# CC27x0 register map
File version: 1.0
CPU: CM4 r0p4, little endian, no MPU, no FPU, VTOR, 3 interrupt priority bits
Registers are 32-bit, read-write, reset 0x0 unless marked. A register's access mark holds for its fields unless they carry their own. Offsets are from the block's base; [hi:lo] are bit positions; {n}, {i} and the like mark numbered series; 'fields as' and 'values as' point back to an identical list.

## CLKCTL — This component is the clock controller. Here SW can turn on and off IP clocks and read IP and system clock status.
Base 0x40020000
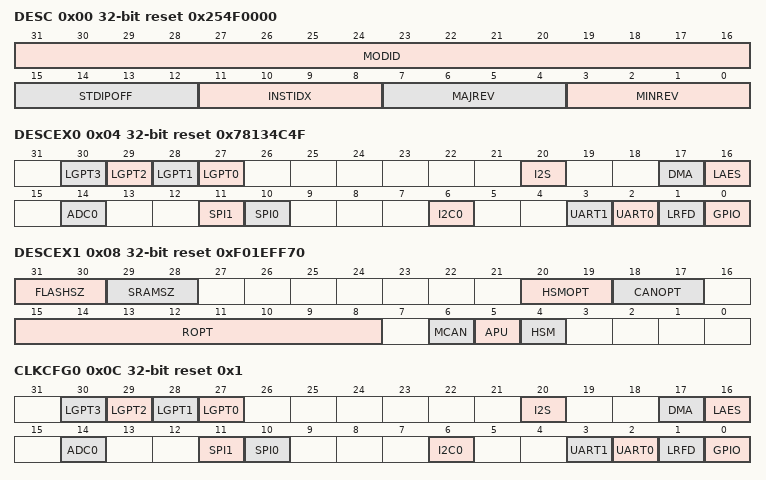
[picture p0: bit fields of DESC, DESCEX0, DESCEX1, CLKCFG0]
0x00 DESC ro reset 0x254F0000 — Description Register. This register provides IP module ID, revision information, instance index and standard MMR registers offset.
  [31:16] MODID — Module identifier used to uniquely identify this IP.
  [15:12] STDIPOFF — Standard IP MMR block offset. Standard IP MMRs are the set of from aggregated IRQ registers till DTB. 0: Standard IP MMRs do not exist 0x1-0xF: Standard IP MMRs begin at offset of (64*STDIPOFF from the base IP address)
  [11:8] INSTIDX — IP Instance ID number. If multiple instances of IP exist in the device, this field can identify the instance number (0-15).
  [7:4] MAJREV — Major revision of IP 0-15
  [3:0] MINREV — Minor revision of IP 0-15.
0x04 DESCEX0 ro reset 0x78134C4F — Extended Description Register 0. This register shows SVT IP availability, HW features and memory size configuration.
  [all] fields
    1=IP_AVAIL (IP is available); 0=IP_UNAVAIL (IP is unavailable)
  [n+27] LGPT{n} (n=0..3) — IP status on device
  [20] I2S — IP status on device
  [17] DMA — IP status on device
  [16] LAES — IP status on device
  [14] ADC0 — IP status on device
  [11] SPI1 — IP status on device
  [10] SPI0 — IP status on device
  [6] I2C0 — IP status on device
  [3] UART1 — IP status on device
  [2] UART0 — IP status on device
  [1] LRFD — IP status on device
  [0] GPIO — IP status on device
0x08 DESCEX1 ro reset 0xF01EFF70 — Extended Description Register 1. This register shows SVT IP availability, HW features and memory size configuration.
  [31:30] FLASHSZ — System flash availability
    3=SZ3 (Flash size set to level 3 (Max size)); 2=SZ2 (Flash size set to level 2); 1=SZ1 (Flash size set to level 1); 0=SZ0 (Flash size set to level 0 (Min size))
  [29:28] SRAMSZ — System SRAM availability
    3=SZ3 (SRAM size set to level 3 (Max size)); 2=SZ2 (SRAM size set to level 2); 1=SZ1 (SRAM size set to level 1); 0=SZ0 (SRAM size set to level 0 (Min size))
  [20:19] HSMOPT — HSM IP feature availability.
    3=MAX (All features available)
  [18:17] CANOPT — CAN IP feature availability
    3=MAX (All features available)
  [15:8] ROPT — System radio feature availability
    255=MAX (All features available)
  [6] MCAN — IP status on device
    values as the fields of DESCEX0
  [5] APU — IP status on device
    values as the fields of DESCEX0
  [4] HSM — IP status on device
    values as the fields of DESCEX0
0x0C CLKCFG0 ro reset 0x1 — Clock Configuration Register 0. This register shows the IP clock configuration for the system. The configuration is updated through CLKENSET0 and CLKENCLR0.
  [all] fields
    1=CLK_EN (Clock is enabled); 0=CLK_DIS (Clock is disabled)
  [n+27] LGPT{n} (n=0..3) — IP clock configuration
  [20] I2S — IP clock configuration
  [17] DMA — IP clock configuration
  [16] LAES — IP clock configuration
  [14] ADC0 — IP clock configuration
  [11] SPI1 — IP clock configuration
  [10] SPI0 — IP clock configuration
  [6] I2C0 — IP clock configuration
  [3] UART1 — IP clock configuration
  [2] UART0 — IP clock configuration
  [1] LRFD — IP clock configuration
  [0] GPIO — IP clock configuration
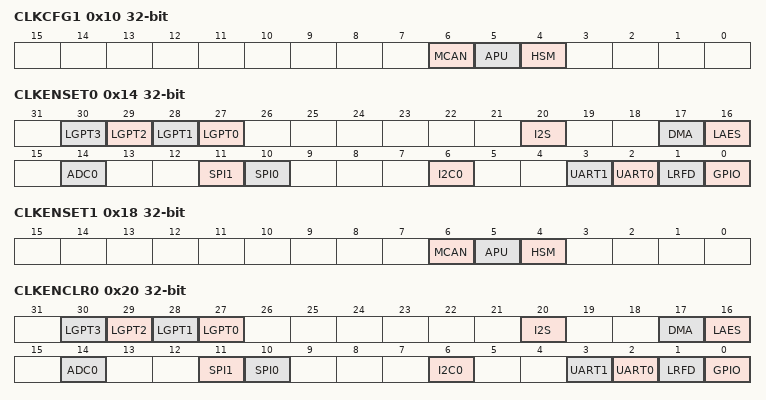
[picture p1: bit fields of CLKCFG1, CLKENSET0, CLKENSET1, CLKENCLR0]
0x10 CLKCFG1 ro — Clock Configuration Register 1. This register shows the IP clock configuration for the system. The configuration is updated through CLKENSET1 and CLKENCLR1.
  [all] fields
    1=CLK_EN (Clock is enabled); 0=CLK_DIS (Clock is disabled)
  [6] MCAN — IP clock configuration
  [5] APU — IP clock configuration
  [4] HSM — IP clock configuration
0x14 CLKENSET0 wo — Clock Enable Set Register 0. This register enables IP clocks in the system. Used to set the corresponding fields in CLKCFG0 to 1.
  [all] fields
    1=CLK_SET (Set IP clock enable); 0=CLK_UNCHGD (IP clock enable is unchanged)
  [n+27] LGPT{n} (n=0..3) — Configure IP clock enable
  [20] I2S — Configure IP clock enable
  [17] DMA — Configure IP clock enable
  [16] LAES — Configure IP clock enable
  [14] ADC0 — Configure IP clock enable
  [11] SPI1 — Configure IP clock enable
  [10] SPI0 — Configure IP clock enable
  [6] I2C0 — Configure IP clock enable
  [3] UART1 — Configure IP clock enable
  [2] UART0 — Configure IP clock enable
  [1] LRFD — Configure IP clock enable
  [0] GPIO — Configure IP clock enable
0x18 CLKENSET1 wo — Clock Enable Set Register 1. This register enables IP clocks in the system. Used to set the corresponding fields in CLKCFG1 to 1.
  [all] fields
    values as the fields of CLKENSET0
  [6] MCAN — Configure IP clock enable
  [5] APU — Configure IP clock enable
  [4] HSM — Configure IP clock enable
0x20 CLKENCLR0 wo — Clock Enable Clear Register 0. This register disables IP clocks in the system. Used to clear the corresponding fields in CLKCFG0 to 0.
  [all] fields
    1=CLK_CLR (Clear IP clock enable); 0=CLK_UNCHGD (IP clock enable is unchanged)
  [n+27] LGPT{n} (n=0..3) — Configure IP clock enable
  [20] I2S — Configure IP clock enable
  [17] DMA — Configure IP clock enable
  [16] LAES — Configure IP clock enable
  [14] ADC0 — Configure IP clock enable
  [11] SPI1 — Configure IP clock enable
  [10] SPI0 — Configure IP clock enable
  [6] I2C0 — Configure IP clock enable
  [3] UART1 — Configure IP clock enable
  [2] UART0 — Configure IP clock enable
  [1] LRFD — Configure IP clock enable
  [0] GPIO — Configure IP clock enable
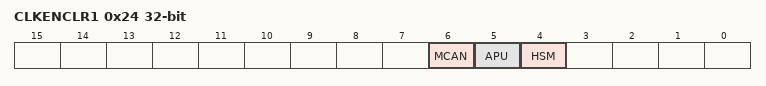
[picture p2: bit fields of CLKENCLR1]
0x24 CLKENCLR1 wo — Clock Enable Clear Register 1. This register disables IP clocks in the system. Used to clear the corresponding fields in CLKCFG1 to 0.
  [all] fields
    values as the fields of CLKENCLR0
  [6] MCAN — Configure IP clock enable
  [5] APU — Configure IP clock enable
  [4] HSM — Configure IP clock enable
0x3C STBYPTR — Internal. Only to be used through TI provided API.
  [31:0] VAL
    0=MIN (Internal. Only to be used through TI provided API.)
0x48 IDLECFG — IDLE Configuration Register. This register contains flash LDO configuration for IDLE mode.
  [0] MODE — Flash LDO configuration in SLEEP/IDLE mode.
    1=LDO_OFF (Flash LDO is off in SLEEP/IDLE mode. Decreases power consumption in SLEEP/IDLE mode, but gives longer wake up time. Note: NVM clock is turned off independent of DMA status. Therefore SW must ensure that DMA never access NVM in this mode.); 0=LDO_ON (Flash LDO is on in SLEEP/IDLE mode. Gives fast wake up time from SLEEP/IDLE mode, but increased power consumption.)
